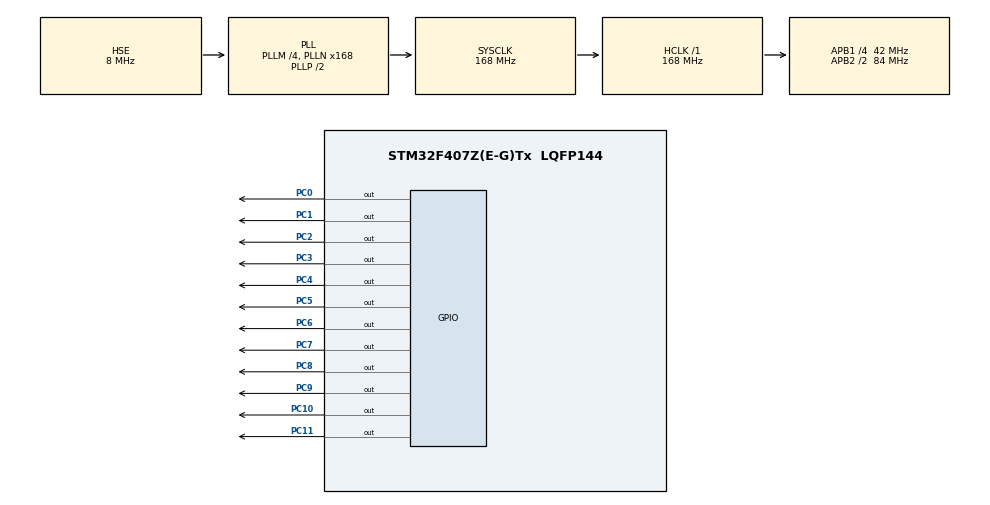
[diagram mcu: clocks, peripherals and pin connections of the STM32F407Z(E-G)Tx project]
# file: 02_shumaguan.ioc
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Mcu.Family=STM32F4
Mcu.Name=STM32F407Z(E-G)Tx
Mcu.Package=LQFP144
NVIC.PriorityGroup=NVIC_PRIORITYGROUP_4
PA13.Mode=Serial_Wire
PA13.Signal=SYS_JTMS-SWDIO
PA14.Mode=Serial_Wire
PA14.Signal=SYS_JTCK-SWCLK
PC0.Signal=GPIO_Output
PC1.Signal=GPIO_Output
PC10.Signal=GPIO_Output
PC11.Signal=GPIO_Output
PC2.Signal=GPIO_Output
PC3.Signal=GPIO_Output
PC4.Signal=GPIO_Output
PC5.Signal=GPIO_Output
PC6.Signal=GPIO_Output
PC7.Signal=GPIO_Output
PC8.Signal=GPIO_Output
PC9.Signal=GPIO_Output
PH0-OSC_IN.Mode=HSE-External-Oscillator
PH0-OSC_IN.Signal=RCC_OSC_IN
PH1-OSC_OUT.Mode=HSE-External-Oscillator
PH1-OSC_OUT.Signal=RCC_OSC_OUT
ProjectManager.HeapSize=0x200
ProjectManager.StackSize=0x400
ProjectManager.TargetToolchain=CMake
RCC.48MHZClocksFreq_Value=84000000
RCC.AHBFreq_Value=168000000
RCC.APB1CLKDivider=RCC_HCLK_DIV4
RCC.APB1Freq_Value=42000000
RCC.APB1TimFreq_Value=84000000
RCC.APB2CLKDivider=RCC_HCLK_DIV2
RCC.APB2Freq_Value=84000000
RCC.APB2TimFreq_Value=168000000
RCC.CortexFreq_Value=168000000
RCC.HCLKFreq_Value=168000000
RCC.HSE_VALUE=8000000
RCC.HSI_VALUE=16000000
RCC.LSE_VALUE=32768
RCC.PLLM=4
RCC.PLLN=168
RCC.PLLSourceVirtual=RCC_PLLSOURCE_HSE
RCC.SYSCLKFreq_VALUE=168000000
RCC.SYSCLKSource=RCC_SYSCLKSOURCE_PLLCLK
RCC.VCOOutputFreq_Value=336000000
board=custom

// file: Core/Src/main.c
/* USER CODE BEGIN Header */
/**
  ******************************************************************************
  * @file           : main.c
  * @brief          : Main program body
  ******************************************************************************
  * @attention
  *
  * Copyright (c) 2025 STMicroelectronics.
  * All rights reserved.
  *
  * This software is licensed under terms that can be found in the LICENSE file
  * in the root directory of this software component.
  * If no LICENSE file comes with this software, it is provided AS-IS.
  *
  ******************************************************************************
  */
/* USER CODE END Header */
#include "main.h"
#include "gpio.h"
#include <stdbool.h>

void SystemClock_Config(void);

//假设我要显示5(也就是n=5)
//那么我要的数据就是0x6D
//也就是zhenzhi[5]
//0x6D的二进制就是 0110 1101
//PC7(控制小数点) 输出低电平
//PC6(控制g) 输出低电平
//PC5(控制f) 输出低电平
//PC4(控制e) 输出低电平
//PC3(控制d) 输出低电平
//PC2(控制c) 输出低电平
//PC1(控制b) 输出低电平
//PC0(控制a) 输出低电平

//定义一个uint8_t类型数组，把0~9ABCEF共16个显示符号的真值遍历出来
uint8_t zhenzhi[16]={0x3F,0x06,0x5B,0x4F,0x66,0x6D,0x7D,0x07,0x7F,0x6F,0x77,0x7C,0x39,0x5E,0x79,0x71};
void Display_Number(uint8_t n,bool Dot)
{
  uint8_t temp=0x01;  //0000 0001
  for (uint8_t i=0;i<8;i++) {
      if (Dot)
      HAL_GPIO_WritePin(GPIOC,(GPIO_PIN_0<<i),((zhenzhi[n] | 0x80 )& (temp<<i))? 1 : 0);
    else
      HAL_GPIO_WritePin(GPIOC,(GPIO_PIN_0<<i),(zhenzhi[n] & (temp<<i))? 1 : 0);
  }

}
int main(void)
{

  /* MCU Configuration--------------------------------------------------------*/

  /* Reset of all peripherals, Initializes the Flash interface and the Systick. */
  HAL_Init();

  /* Configure the system clock */
  SystemClock_Config();

  /* Initialize all configured peripherals */
  MX_GPIO_Init();

  /* Infinite loop */
  /* USER CODE BEGIN WHILE */
  while (1)
  {
    for (int i=0;i<16;i++) {
      Display_Number(i,1);
      HAL_Delay(500);
      Display_Number(i,0);
      HAL_Delay(500);
    }

    /* USER CODE END WHILE */

  }
}

void SystemClock_Config(void)
{
  RCC_OscInitTypeDef RCC_OscInitStruct = {0};
  RCC_ClkInitTypeDef RCC_ClkInitStruct = {0};

  /** Configure the main internal regulator output voltage
  */
  __HAL_RCC_PWR_CLK_ENABLE();
  __HAL_PWR_VOLTAGESCALING_CONFIG(PWR_REGULATOR_VOLTAGE_SCALE1);

  /** Initializes the RCC Oscillators according to the specified parameters
  * in the RCC_OscInitTypeDef structure.
  */
  RCC_OscInitStruct.OscillatorType = RCC_OSCILLATORTYPE_HSE;
  RCC_OscInitStruct.HSEState = RCC_HSE_ON;
  RCC_OscInitStruct.PLL.PLLState = RCC_PLL_ON;
  RCC_OscInitStruct.PLL.PLLSource = RCC_PLLSOURCE_HSE;
  RCC_OscInitStruct.PLL.PLLM = 4;
  RCC_OscInitStruct.PLL.PLLN = 168;
  RCC_OscInitStruct.PLL.PLLP = RCC_PLLP_DIV2;
  RCC_OscInitStruct.PLL.PLLQ = 4;
  if (HAL_RCC_OscConfig(&RCC_OscInitStruct) != HAL_OK)
  {
    Error_Handler();
  }

  /** Initializes the CPU, AHB and APB buses clocks
  */
  RCC_ClkInitStruct.ClockType = RCC_CLOCKTYPE_HCLK|RCC_CLOCKTYPE_SYSCLK
                              |RCC_CLOCKTYPE_PCLK1|RCC_CLOCKTYPE_PCLK2;
  RCC_ClkInitStruct.SYSCLKSource = RCC_SYSCLKSOURCE_PLLCLK;
  RCC_ClkInitStruct.AHBCLKDivider = RCC_SYSCLK_DIV1;
  RCC_ClkInitStruct.APB1CLKDivider = RCC_HCLK_DIV4;
  RCC_ClkInitStruct.APB2CLKDivider = RCC_HCLK_DIV2;

  if (HAL_RCC_ClockConfig(&RCC_ClkInitStruct, FLASH_LATENCY_5) != HAL_OK)
  {
    Error_Handler();
  }
}

void Error_Handler(void)
{
  __disable_irq();
  while (1)
  {
  }
}
